# CY8C5888LTI_LP097 register map
File version: 0.1
CY8C58LP
Registers are 32-bit, read-write, no defined reset value unless marked. A register's access mark holds for its fields unless they carry their own. Offsets are from the block's base; lines under a group give offsets from that group; [hi:lo] are bit positions; {n}, {i} and the like mark numbered series; 'fields as' and 'values as' point back to an identical list; <NAME> marks a mode.

## Memory map
0x00000000 power_comp
0x00000000 time_refresh_timer
0x00000000 xbee_UART — UART
0x00000000 USBUART_1 — USBFS
0x00000000 CAN_1
0x00000000 millis_timer
0x00000000 rtc_i2c

## time_refresh_timer
Base 0x00000000
0x40006507 time_refresh_timer_COUNTER 16-bit — UDB.A0 - Current Down Counter Value
0x40006527 time_refresh_timer_PERIOD 16-bit — UDB.D0 - Assigned Period
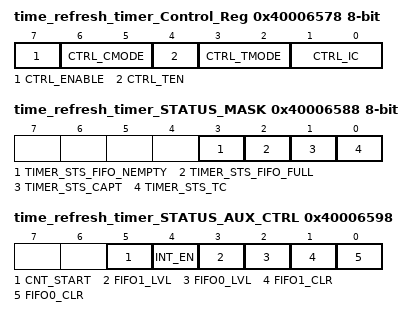
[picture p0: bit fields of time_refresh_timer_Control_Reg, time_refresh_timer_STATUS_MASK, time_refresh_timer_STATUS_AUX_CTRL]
0x40006578 time_refresh_timer_Control_Reg 8-bit — UDB Control Register - Assigned Control Register Value
  [7] CTRL_ENABLE — Enable the Timer
  [6:5] CTRL_CMODE — Capture Mode
  [4] CTRL_TEN — Trigger Enable Bit
  [3:2] CTRL_TMODE — Trigger Mode
  [1:0] CTRL_IC — Interrupt Count
0x40006588 time_refresh_timer_STATUS_MASK 8-bit — UDB Status bits Interrupt Mask Enable Register
  [3] TIMER_STS_FIFO_NEMPTY ro — FIFO Empty status
  [2] TIMER_STS_FIFO_FULL ro — FIFO Full Status
  [1] TIMER_STS_CAPT ro — Enables the Interrupt on Capture
  [0] TIMER_STS_TC ro — Enables the Interrupt on TC
0x40006598 time_refresh_timer_STATUS_AUX_CTRL 8-bit — UDB Auxilliary Control Register
  [5] CNT_START — FIFO0 clear
    0=E_CNT_START0 (Disable counter); 1=E_CNT_START1 (Enable counter)
  [4] INT_EN
    0=E_INT_EN0 (Interrupt disabled); 1=E_INT_EN1 (Interrupt enabled)
  [3] FIFO1_LVL — FIFO level
    0=E_FIFO_LVL_0 (FIFO LVL: input mode: FIFO not full; output mode: FIFO not empty); 1=E_FIFO_LVL_1 (FIFO LVL: input mode: FIFO at least 1/2 empty; output mode: FIFO at least 1/2 full)
  [2] FIFO0_LVL — FIFO level
    values as FIFO1_LVL
  [1] FIFO1_CLR — FIFO1 clear
    0=E_FIFO_CLR_0 (Normal FIFO operation); 1=E_FIFO_CLR_1 (Clear FIFO state)
  [0] FIFO0_CLR — FIFO0 clear
    values as FIFO1_CLR

## xbee_UART — UART
Base 0x00000000
0x40006429 RX_xbee_UART_RX_ADDRESS1 8-bit — RX Address1 Register
0x40006439 RX_xbee_UART_RX_ADDRESS2 8-bit — RX Address2 Register
0x40006446 TX_xbee_UART_TX_DATA 8-bit — TX Data Register
0x40006449 RX_xbee_UART_RX_DATA 8-bit — RX Data Register
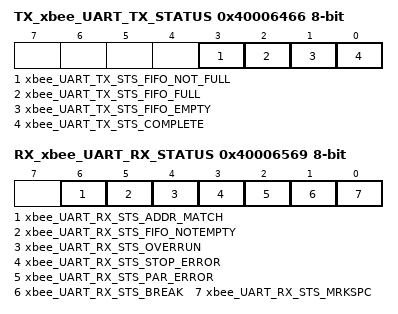
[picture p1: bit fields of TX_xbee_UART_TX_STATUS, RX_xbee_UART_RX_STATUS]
0x40006466 TX_xbee_UART_TX_STATUS 8-bit — TX status register
  [3] xbee_UART_TX_STS_FIFO_NOT_FULL ro, [2] xbee_UART_TX_STS_FIFO_FULL ro, [1] xbee_UART_TX_STS_FIFO_EMPTY ro, [0] xbee_UART_TX_STS_COMPLETE ro
0x40006569 RX_xbee_UART_RX_STATUS 8-bit — RX status register
  [6] xbee_UART_RX_STS_ADDR_MATCH ro, [5] xbee_UART_RX_STS_FIFO_NOTEMPTY ro, [4] xbee_UART_RX_STS_OVERRUN ro, [3] xbee_UART_RX_STS_STOP_ERROR ro, [2] xbee_UART_RX_STS_PAR_ERROR ro, [1] xbee_UART_RX_STS_BREAK ro, [0] xbee_UART_RX_STS_MRKSPC ro

## USBUART_1 — USBFS
Base 0x00000000
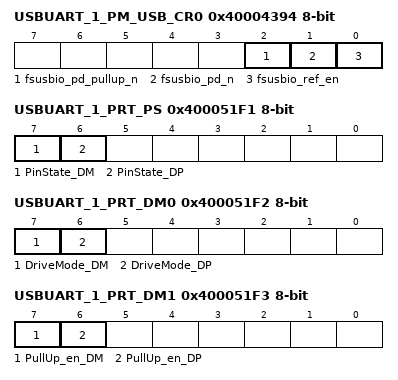
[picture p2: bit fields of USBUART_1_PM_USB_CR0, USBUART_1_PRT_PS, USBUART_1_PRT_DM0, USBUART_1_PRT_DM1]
0x40004394 USBUART_1_PM_USB_CR0 8-bit — USB Power Mode Control Register 0
  [2] fsusbio_pd_pullup_n, [1] fsusbio_pd_n, [0] fsusbio_ref_en
0x400043A5 USBUART_1_PM_ACT_CFG 8-bit — Active Power Mode Configuration Register
0x400043B5 USBUART_1_PM_STBY_CFG 8-bit — Standby Power Mode Configuration Register
0x400051F1 USBUART_1_PRT_PS 8-bit — Port Pin State Register
  [7] PinState_DM ro, [6] PinState_DP ro
0x400051F2 USBUART_1_PRT_DM0 8-bit — Port Drive Mode Register
  [7] DriveMode_DM, [6] DriveMode_DP
0x400051F3 USBUART_1_PRT_DM1 8-bit — Port Drive Mode Register
  [7] PullUp_en_DM, [6] PullUp_en_DP
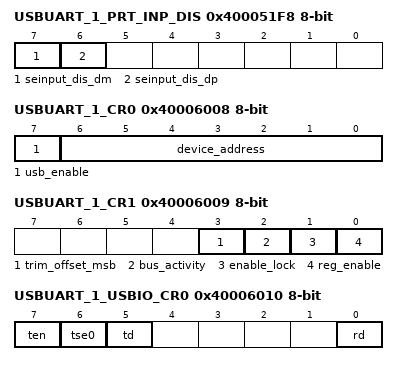
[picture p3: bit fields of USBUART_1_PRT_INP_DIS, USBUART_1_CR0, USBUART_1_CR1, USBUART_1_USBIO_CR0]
0x400051F8 USBUART_1_PRT_INP_DIS 8-bit — Input buffer disable override
  [7] seinput_dis_dm, [6] seinput_dis_dp
0x40006000 USBUART_1_EP0_DR0 8-bit — bmRequestType
0x40006001 USBUART_1_EP0_DR1 8-bit — bRequest
0x40006002 USBUART_1_EP0_DR2 8-bit — wValueLo
0x40006003 USBUART_1_EP0_DR3 8-bit — wValueHi
0x40006004 USBUART_1_EP0_DR4 8-bit — wIndexLo
0x40006005 USBUART_1_EP0_DR5 8-bit — wIndexHi
0x40006006 USBUART_1_EP0_DR6 8-bit — lengthLo
0x40006007 USBUART_1_EP0_DR7 8-bit — lengthHi
0x40006008 USBUART_1_CR0 8-bit — USB Control Register 0
  [7] usb_enable, [6:0] device_address ro
0x40006009 USBUART_1_CR1 8-bit — USB Control Register 1
  [3] trim_offset_msb, [2] bus_activity, [1] enable_lock, [0] reg_enable
{0x40005FFE+0x10*i} USBUART_1_SIE_EP{i}_CR0 8-bit (i=1..8) — The Endpoint{i} Control Register
0x40006010 USBUART_1_USBIO_CR0 8-bit — USBIO Control Register 0
  [7] ten, [6] tse0, [5] td, [0] rd ro
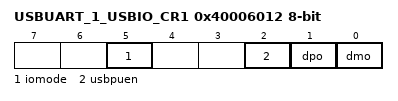
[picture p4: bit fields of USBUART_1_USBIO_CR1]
0x40006012 USBUART_1_USBIO_CR1 8-bit — USBIO Control Register 1
  [5] iomode, [2] usbpuen, [1] dpo ro, [0] dmo ro
0x4000608C USBUART_1_BUF_SIZE 8-bit — Dedicated Endpoint Buffer Size Register
0x4000608E USBUART_1_EP_ACTIVE 8-bit — Endpoint Active Indication Register
0x4000608F USBUART_1_EP_TYPE 8-bit — Endpoint Type (IN/OUT) Indication
0x4000609D USBUART_1_USB_CLK_EN 8-bit — USB Block Clock Enable Register
